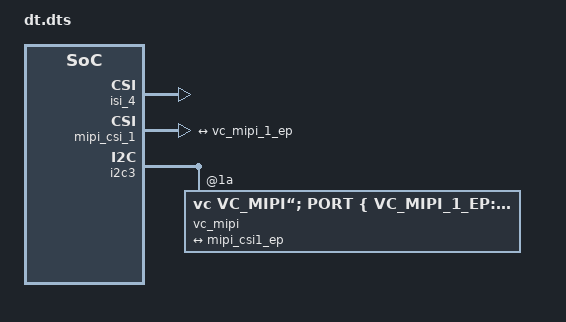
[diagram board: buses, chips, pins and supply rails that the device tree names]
img_subsys: bus@58000000 {
        compatible = "simple-bus";
	cameradev: camera {
                compatible = "fsl,mxc-md", "simple-bus";
		isi_4: isi@58140000 {
                        compatible = "fsl,imx8-isi";
		 	interface = <3 0 2>;
			cap_device { }; 
		};

		mipi_csi_1: csi@58247000 {
                        compatible = "fsl,mxc-mipi-csi2";
			port@1 { 
				mipi_csi1_ep: endpoint { 
					remote-endpoint = <&vc_mipi_1_ep>; 
				}; 
			};
		};
        }
}

dma_subsys: bus@5a000000 {
        i2c3: i2c@5a830000 {
                compatible = "fsl,imx8qm-lpi2c", "fsl,imx7ulp-lpi2c";
                vc_mipi@1a {
                        compatible = "vc,vc_mipi“;	
                        port {
                                vc_mipi_1_ep: endpoint {
                                        remote-endpoint = <&mipi_csi1_ep>;
                                };
                        };
                };
        };
};


// ****************************************************************************

camera: camera {
        compatible = "fsl,mxc-md", "simple-bus";
        isi_4: isi@58140000 {
                compatible = "fsl,imx8-isi";
	        interface = <3 0 2>;
        };
        mipi_csi_1: csi@58247000 {
                compatible = "fsl,mxc-mipi-csi2";
                port@0 {
                        mipi_csi1_ep: endpoint {
                                remote-endpoint = <&avt_csi2_ep>;
                        };
                };
        };
};

i2c3: i2c@5a830000 {
        compatible = "fsl,imx8qm-lpi2c", "fsl,imx7ulp-lpi2c";
	avt_csi2@3c {
		compatible = "alliedvision,avt_csi2";
		port {
			avt_csi2_ep: endpoint {

				remote-endpoint = <&mipi_csi1_ep>;
			};
		};
	};
};
